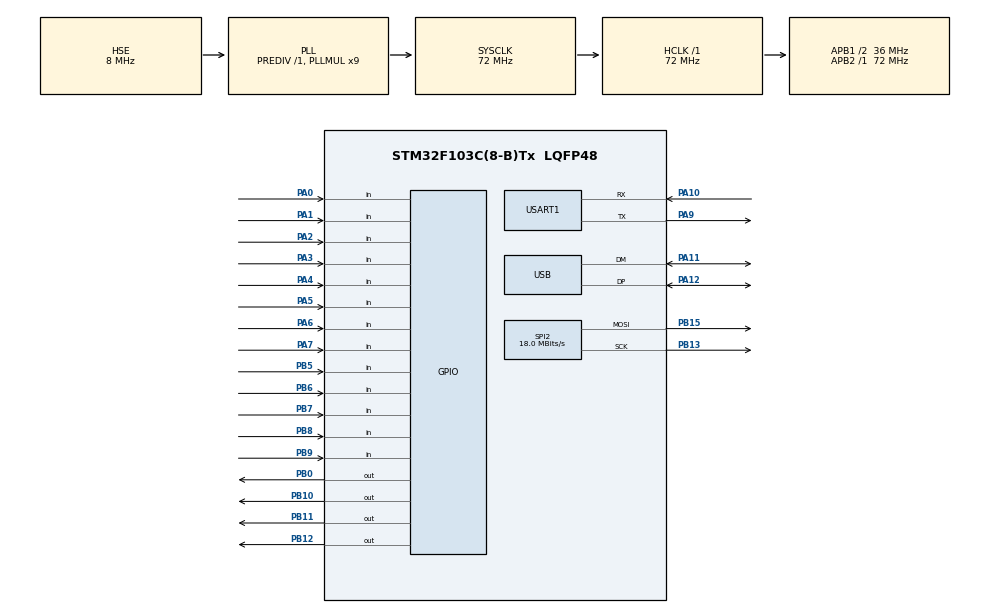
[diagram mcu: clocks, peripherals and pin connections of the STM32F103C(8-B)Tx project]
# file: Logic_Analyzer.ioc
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Dma.Request0=TIM2_UP
Dma.TIM2_UP.0.Direction=DMA_PERIPH_TO_MEMORY
Dma.TIM2_UP.0.Instance=DMA1_Channel2
Dma.TIM2_UP.0.MemDataAlignment=DMA_MDATAALIGN_BYTE
Dma.TIM2_UP.0.MemInc=DMA_MINC_ENABLE
Dma.TIM2_UP.0.Mode=DMA_CIRCULAR
Dma.TIM2_UP.0.PeriphDataAlignment=DMA_PDATAALIGN_HALFWORD
Dma.TIM2_UP.0.PeriphInc=DMA_PINC_DISABLE
Dma.TIM2_UP.0.Priority=DMA_PRIORITY_VERY_HIGH
Mcu.Family=STM32F1
Mcu.Name=STM32F103C(8-B)Tx
Mcu.Package=LQFP48
NVIC.DMA1_Channel2_IRQn=true\:0\:0\:false\:false\:true\:false\:true\:true
NVIC.PriorityGroup=NVIC_PRIORITYGROUP_4
NVIC.USART1_IRQn=true\:2\:0\:true\:false\:true\:true\:true\:true
NVIC.USB_LP_CAN1_RX0_IRQn=true\:2\:0\:true\:false\:true\:false\:true\:true
PA0-WKUP.Signal=GPIO_Input
PA1.Signal=GPIO_Input
PA10.Mode=Asynchronous
PA10.Signal=USART1_RX
PA11.Mode=Device
PA11.Signal=USB_DM
PA12.Mode=Device
PA12.Signal=USB_DP
PA13.Mode=Serial_Wire
PA13.Signal=SYS_JTMS-SWDIO
PA14.Mode=Serial_Wire
PA14.Signal=SYS_JTCK-SWCLK
PA2.Signal=GPIO_Input
PA3.Signal=GPIO_Input
PA4.Signal=GPIO_Input
PA5.Signal=GPIO_Input
PA6.Signal=GPIO_Input
PA7.Signal=GPIO_Input
PA9.Mode=Asynchronous
PA9.Signal=USART1_TX
PB0.Signal=GPIO_Output
PB10.Signal=GPIO_Output
PB11.Signal=GPIO_Output
PB12.Signal=GPIO_Output
PB13.Mode=TX_Only_Simplex_Unidirect_Master
PB13.Signal=SPI2_SCK
PB15.Mode=TX_Only_Simplex_Unidirect_Master
PB15.Signal=SPI2_MOSI
PB5.GPIO_PuPd=GPIO_PULLUP
PB5.Signal=GPIO_Input
PB6.GPIO_PuPd=GPIO_PULLUP
PB6.Signal=GPIO_Input
PB7.GPIO_PuPd=GPIO_PULLUP
PB7.Signal=GPIO_Input
PB8.GPIO_PuPd=GPIO_PULLUP
PB8.Signal=GPIO_Input
PB9.GPIO_PuPd=GPIO_PULLUP
PB9.Signal=GPIO_Input
PD0-OSC_IN.Mode=HSE-External-Oscillator
PD0-OSC_IN.Signal=RCC_OSC_IN
PD1-OSC_OUT.Mode=HSE-External-Oscillator
PD1-OSC_OUT.Signal=RCC_OSC_OUT
ProjectManager.HeapSize=0x200
ProjectManager.StackSize=0x400
ProjectManager.TargetToolchain=MDK-ARM V5.32
RCC.AHBFreq_Value=72000000
RCC.APB1CLKDivider=RCC_HCLK_DIV2
RCC.APB1Freq_Value=36000000
RCC.APB1TimFreq_Value=72000000
RCC.APB2Freq_Value=72000000
RCC.APB2TimFreq_Value=72000000
RCC.HCLKFreq_Value=72000000
RCC.PLLMUL=RCC_PLL_MUL9
RCC.PLLSourceVirtual=RCC_PLLSOURCE_HSE
RCC.SYSCLKFreq_VALUE=72000000
RCC.SYSCLKSource=RCC_SYSCLKSOURCE_PLLCLK
RCC.USBFreq_Value=48000000
RCC.USBPrescaler=RCC_USBCLKSOURCE_PLL_DIV1_5
SPI2.CalculateBaudRate=18.0 MBits/s
SPI2.Direction=SPI_DIRECTION_2LINES
SPI2.Mode=SPI_MODE_MASTER
SPI2.VirtualType=VM_MASTER
TIM2.Period=71
USART1.VirtualMode=VM_ASYNC
USB_DEVICE.CLASS_NAME_FS=CDC
USB_DEVICE.VirtualMode=Cdc
USB_DEVICE.VirtualModeFS=Cdc_FS
VP_TIM2_VS_ClockSourceINT.Mode=Internal
VP_USB_DEVICE_VS_USB_DEVICE_CDC_FS.Mode=CDC_FS
board=custom

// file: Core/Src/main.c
/* USER CODE BEGIN Header */
/**
  ******************************************************************************
  * @file           : main.c
  * @brief          : Main program body
  ******************************************************************************
  * @attention
  *
  * Copyright (c) 2026 STMicroelectronics.
  * All rights reserved.
  *
  * This software is licensed under terms that can be found in the LICENSE file
  * in the root directory of this software component.
  * If no LICENSE file comes with this software, it is provided AS-IS.
  *
  ******************************************************************************
  */
/* USER CODE END Header */
#include "main.h"
#include "usb_device.h"

/* USER CODE BEGIN Includes */
#include "acquisition.h"
#include "pc_interface.h"
#include "self_test.h"
#include "display_control.h"
/* USER CODE END Includes */

SPI_HandleTypeDef hspi2;

TIM_HandleTypeDef htim2;
DMA_HandleTypeDef hdma_tim2_up;

UART_HandleTypeDef huart1;

void SystemClock_Config(void);
static void MX_GPIO_Init(void);
static void MX_DMA_Init(void);
static void MX_TIM2_Init(void);
static void MX_SPI2_Init(void);
static void MX_USART1_UART_Init(void);

int main(void)
{

  /* MCU Configuration--------------------------------------------------------*/

  /* Reset of all peripherals, Initializes the Flash interface and the Systick. */
  HAL_Init();

  /* Configure the system clock */
  SystemClock_Config();

  /* Initialize all configured peripherals */
  MX_GPIO_Init();
  MX_DMA_Init();
  MX_TIM2_Init();
  MX_SPI2_Init();
  MX_USART1_UART_Init();
  MX_USB_DEVICE_Init();
  /* USER CODE BEGIN 2 */
  LA_Init(&htim2, &hdma_tim2_up);
  PC_Init();
  SelfTest_Init(&huart1, &hspi2);
  // Display_Init(&hspi2);
/* USER CODE END 2 */

  /* Infinite loop */
  while (1)
  {

    /* USER CODE BEGIN 3 */
    LA_Task();
    PC_Task();
    SelfTest_Task();
    // Display_Task();
  }
/* USER CODE END 3 */
}

void SystemClock_Config(void)
{
  RCC_OscInitTypeDef RCC_OscInitStruct = {0};
  RCC_ClkInitTypeDef RCC_ClkInitStruct = {0};
  RCC_PeriphCLKInitTypeDef PeriphClkInit = {0};

  /** Initializes the RCC Oscillators according to the specified parameters
  * in the RCC_OscInitTypeDef structure.
  */
  RCC_OscInitStruct.OscillatorType = RCC_OSCILLATORTYPE_HSE;
  RCC_OscInitStruct.HSEState = RCC_HSE_ON;
  RCC_OscInitStruct.HSEPredivValue = RCC_HSE_PREDIV_DIV1;
  RCC_OscInitStruct.HSIState = RCC_HSI_ON;
  RCC_OscInitStruct.PLL.PLLState = RCC_PLL_ON;
  RCC_OscInitStruct.PLL.PLLSource = RCC_PLLSOURCE_HSE;
  RCC_OscInitStruct.PLL.PLLMUL = RCC_PLL_MUL9;
  if (HAL_RCC_OscConfig(&RCC_OscInitStruct) != HAL_OK)
  {
    Error_Handler();
  }

  /** Initializes the CPU, AHB and APB buses clocks
  */
  RCC_ClkInitStruct.ClockType = RCC_CLOCKTYPE_HCLK|RCC_CLOCKTYPE_SYSCLK
                              |RCC_CLOCKTYPE_PCLK1|RCC_CLOCKTYPE_PCLK2;
  RCC_ClkInitStruct.SYSCLKSource = RCC_SYSCLKSOURCE_PLLCLK;
  RCC_ClkInitStruct.AHBCLKDivider = RCC_SYSCLK_DIV1;
  RCC_ClkInitStruct.APB1CLKDivider = RCC_HCLK_DIV2;
  RCC_ClkInitStruct.APB2CLKDivider = RCC_HCLK_DIV1;

  if (HAL_RCC_ClockConfig(&RCC_ClkInitStruct, FLASH_LATENCY_2) != HAL_OK)
  {
    Error_Handler();
  }
  PeriphClkInit.PeriphClockSelection = RCC_PERIPHCLK_USB;
  PeriphClkInit.UsbClockSelection = RCC_USBCLKSOURCE_PLL_DIV1_5;
  if (HAL_RCCEx_PeriphCLKConfig(&PeriphClkInit) != HAL_OK)
  {
    Error_Handler();
  }
}

static void MX_SPI2_Init(void)
{

  /* SPI2 parameter configuration*/
  hspi2.Instance = SPI2;
  hspi2.Init.Mode = SPI_MODE_MASTER;
  hspi2.Init.Direction = SPI_DIRECTION_2LINES;
  hspi2.Init.DataSize = SPI_DATASIZE_8BIT;
  hspi2.Init.CLKPolarity = SPI_POLARITY_LOW;
  hspi2.Init.CLKPhase = SPI_PHASE_1EDGE;
  hspi2.Init.NSS = SPI_NSS_SOFT;
  hspi2.Init.BaudRatePrescaler = SPI_BAUDRATEPRESCALER_2;
  hspi2.Init.FirstBit = SPI_FIRSTBIT_MSB;
  hspi2.Init.TIMode = SPI_TIMODE_DISABLE;
  hspi2.Init.CRCCalculation = SPI_CRCCALCULATION_DISABLE;
  hspi2.Init.CRCPolynomial = 10;
  if (HAL_SPI_Init(&hspi2) != HAL_OK)
  {
    Error_Handler();
  }

}

static void MX_TIM2_Init(void)
{

  TIM_ClockConfigTypeDef sClockSourceConfig = {0};
  TIM_MasterConfigTypeDef sMasterConfig = {0};

  htim2.Instance = TIM2;
  htim2.Init.Prescaler = 0;
  htim2.Init.CounterMode = TIM_COUNTERMODE_UP;
  htim2.Init.Period = 71;
  htim2.Init.ClockDivision = TIM_CLOCKDIVISION_DIV1;
  htim2.Init.AutoReloadPreload = TIM_AUTORELOAD_PRELOAD_DISABLE;
  if (HAL_TIM_Base_Init(&htim2) != HAL_OK)
  {
    Error_Handler();
  }
  sClockSourceConfig.ClockSource = TIM_CLOCKSOURCE_INTERNAL;
  if (HAL_TIM_ConfigClockSource(&htim2, &sClockSourceConfig) != HAL_OK)
  {
    Error_Handler();
  }
  sMasterConfig.MasterOutputTrigger = TIM_TRGO_RESET;
  sMasterConfig.MasterSlaveMode = TIM_MASTERSLAVEMODE_DISABLE;
  if (HAL_TIMEx_MasterConfigSynchronization(&htim2, &sMasterConfig) != HAL_OK)
  {
    Error_Handler();
  }

}

static void MX_USART1_UART_Init(void)
{

  huart1.Instance = USART1;
  huart1.Init.BaudRate = 115200;
  huart1.Init.WordLength = UART_WORDLENGTH_8B;
  huart1.Init.StopBits = UART_STOPBITS_1;
  huart1.Init.Parity = UART_PARITY_NONE;
  huart1.Init.Mode = UART_MODE_TX_RX;
  huart1.Init.HwFlowCtl = UART_HWCONTROL_NONE;
  huart1.Init.OverSampling = UART_OVERSAMPLING_16;
  if (HAL_UART_Init(&huart1) != HAL_OK)
  {
    Error_Handler();
  }

}

static void MX_DMA_Init(void)
{

  /* DMA controller clock enable */
  __HAL_RCC_DMA1_CLK_ENABLE();

  /* DMA interrupt init */
  /* DMA1_Channel2_IRQn interrupt configuration */
  HAL_NVIC_SetPriority(DMA1_Channel2_IRQn, 0, 0);
  HAL_NVIC_EnableIRQ(DMA1_Channel2_IRQn);

}

static void MX_GPIO_Init(void)
{
  GPIO_InitTypeDef GPIO_InitStruct = {0};

  /* GPIO Ports Clock Enable */
  __HAL_RCC_GPIOD_CLK_ENABLE();
  __HAL_RCC_GPIOA_CLK_ENABLE();
  __HAL_RCC_GPIOB_CLK_ENABLE();

  /*Configure GPIO pin Output Level */
  HAL_GPIO_WritePin(GPIOB, GPIO_PIN_0|GPIO_PIN_10|GPIO_PIN_11|GPIO_PIN_12, GPIO_PIN_RESET);

  /*Configure GPIO pins : PA0 PA1 PA2 PA3
                           PA4 PA5 PA6 PA7 */
  GPIO_InitStruct.Pin = GPIO_PIN_0|GPIO_PIN_1|GPIO_PIN_2|GPIO_PIN_3
                          |GPIO_PIN_4|GPIO_PIN_5|GPIO_PIN_6|GPIO_PIN_7;
  GPIO_InitStruct.Mode = GPIO_MODE_INPUT;
  GPIO_InitStruct.Pull = GPIO_NOPULL;
  HAL_GPIO_Init(GPIOA, &GPIO_InitStruct);

  /*Configure GPIO pins : PB0 PB10 PB11 PB12 */
  GPIO_InitStruct.Pin = GPIO_PIN_0|GPIO_PIN_10|GPIO_PIN_11|GPIO_PIN_12;
  GPIO_InitStruct.Mode = GPIO_MODE_OUTPUT_PP;
  GPIO_InitStruct.Pull = GPIO_NOPULL;
  GPIO_InitStruct.Speed = GPIO_SPEED_FREQ_LOW;
  HAL_GPIO_Init(GPIOB, &GPIO_InitStruct);

  /*Configure GPIO pins : PB5 PB6 PB7 PB8
                           PB9 */
  GPIO_InitStruct.Pin = GPIO_PIN_5|GPIO_PIN_6|GPIO_PIN_7|GPIO_PIN_8
                          |GPIO_PIN_9;
  GPIO_InitStruct.Mode = GPIO_MODE_INPUT;
  GPIO_InitStruct.Pull = GPIO_PULLUP;
  HAL_GPIO_Init(GPIOB, &GPIO_InitStruct);

}

void Error_Handler(void)
{
  __disable_irq();
  while (1)
  {
  }
}
